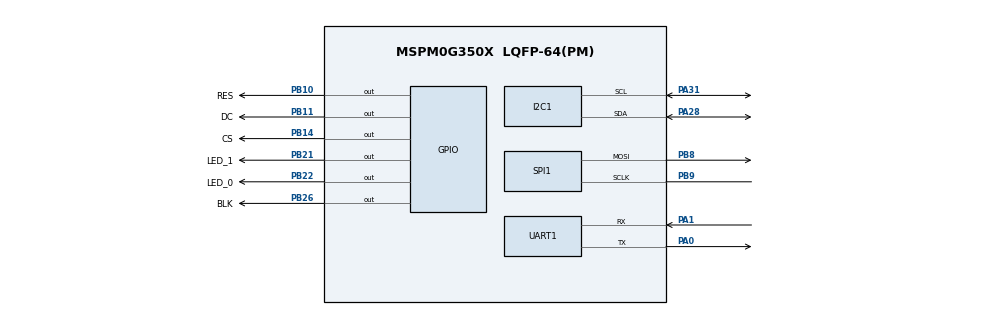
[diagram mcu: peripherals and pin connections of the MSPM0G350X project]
/**
 * @cliArgs --device "MSPM0G350X" --part "Default" --package "LQFP-64(PM)" --product "mspm0_sdk@2.10.00.04"
 * @versions {"tool":"1.26.2+4477"}
 */

/**
 * Import the modules used in this configuration.
 */
const GPIO   = scripting.addModule("/ti/driverlib/GPIO", {}, false);
const GPIO1  = GPIO.addInstance();
const GPIO2  = GPIO.addInstance();
const I2C    = scripting.addModule("/ti/driverlib/I2C", {}, false);
const I2C1   = I2C.addInstance();
const SPI    = scripting.addModule("/ti/driverlib/SPI", {}, false);
const SPI1   = SPI.addInstance();
const SYSCTL = scripting.addModule("/ti/driverlib/SYSCTL");
const UART   = scripting.addModule("/ti/driverlib/UART", {}, false);
const UART1  = UART.addInstance();

/**
 * Write custom configuration values to the imported modules.
 */
const divider9       = system.clockTree["UDIV"];
divider9.divideValue = 2;

const multiplier2         = system.clockTree["PLL_QDIV"];
multiplier2.multiplyValue = 4;

const mux4       = system.clockTree["EXHFMUX"];
mux4.inputSelect = "EXHFMUX_XTAL";

const mux8       = system.clockTree["HSCLKMUX"];
mux8.inputSelect = "HSCLKMUX_SYSPLL0";

const mux12       = system.clockTree["SYSPLLMUX"];
mux12.inputSelect = "zSYSPLLMUX_HFCLK";

const pinFunction4     = system.clockTree["HFXT"];
pinFunction4.inputFreq = 40;
pinFunction4.enable    = true;

GPIO1.$name                         = "LED";
GPIO1.associatedPins.create(2);
GPIO1.associatedPins[0].$name       = "LED_0";
GPIO1.associatedPins[0].pin.$assign = "PB22";
GPIO1.associatedPins[1].$name       = "LED_1";
GPIO1.associatedPins[1].pin.$assign = "PB21";

const Board = scripting.addModule("/ti/driverlib/Board", {}, false);

GPIO2.$name                         = "TFT_3";
GPIO2.associatedPins.create(4);
GPIO2.associatedPins[0].$name       = "RES";
GPIO2.associatedPins[0].pin.$assign = "PB10";
GPIO2.associatedPins[1].$name       = "DC";
GPIO2.associatedPins[1].pin.$assign = "PB11";
GPIO2.associatedPins[2].$name       = "CS";
GPIO2.associatedPins[2].pin.$assign = "PB14";
GPIO2.associatedPins[3].$name       = "BLK";
GPIO2.associatedPins[3].pin.$assign = "PB26";

I2C1.$name                             = "OLED";
I2C1.basicEnableController             = true;
I2C1.advDigitalGlitchFilter            = "CLOCKS_1";
I2C1.advControllerRXFIFOTRIG           = "BYTES_8";
I2C1.advControllerTXFIFOTRIG           = "BYTES_7";
I2C1.enableDMAEvent1                   = false;
I2C1.enableDMAEvent2                   = false;
I2C1.basicControllerStandardBusSpeed   = "Standard";
I2C1.peripheral.sdaPin.$assign         = "PA28";
I2C1.peripheral.sclPin.$assign         = "PA31";
I2C1.sdaPinConfig.$name                = "ti_driverlib_gpio_GPIOPinGeneric0";
I2C1.sdaPinConfig.hideOutputInversion  = scripting.forceWrite(false);
I2C1.sdaPinConfig.onlyInternalResistor = scripting.forceWrite(false);
I2C1.sdaPinConfig.passedPeripheralType = scripting.forceWrite("Digital");
I2C1.sdaPinConfig.enableConfig         = true;
I2C1.sdaPinConfig.internalResistor     = "PULL_UP";
I2C1.sclPinConfig.$name                = "ti_driverlib_gpio_GPIOPinGeneric1";
I2C1.sclPinConfig.hideOutputInversion  = scripting.forceWrite(false);
I2C1.sclPinConfig.onlyInternalResistor = scripting.forceWrite(false);
I2C1.sclPinConfig.passedPeripheralType = scripting.forceWrite("Digital");
I2C1.sclPinConfig.enableConfig         = true;
I2C1.sclPinConfig.internalResistor     = "PULL_UP";

SPI1.$name                              = "TFT";
SPI1.peripheral.$assign                 = "SPI1";
SPI1.peripheral.sclkPin.$assign         = "PB9";
SPI1.peripheral.mosiPin.$assign         = "PB8";
SPI1.sclkPinConfig.$name                = "ti_driverlib_gpio_GPIOPinGeneric2";
SPI1.sclkPinConfig.direction            = scripting.forceWrite("OUTPUT");
SPI1.sclkPinConfig.onlyInternalResistor = scripting.forceWrite(false);
SPI1.sclkPinConfig.passedPeripheralType = scripting.forceWrite("Digital");
SPI1.mosiPinConfig.$name                = "ti_driverlib_gpio_GPIOPinGeneric3";
SPI1.mosiPinConfig.direction            = scripting.forceWrite("OUTPUT");
SPI1.mosiPinConfig.hideOutputInversion  = scripting.forceWrite(false);
SPI1.mosiPinConfig.onlyInternalResistor = scripting.forceWrite(false);
SPI1.mosiPinConfig.passedPeripheralType = scripting.forceWrite("Digital");
SPI1.misoPinConfig.$name                = "ti_driverlib_gpio_GPIOPinGeneric4";
SPI1.misoPinConfig.onlyInternalResistor = scripting.forceWrite(false);
SPI1.misoPinConfig.passedPeripheralType = scripting.forceWrite("Digital");
SPI1.cs0PinConfig.$name                 = "ti_driverlib_gpio_GPIOPinGeneric5";
SPI1.cs0PinConfig.direction             = scripting.forceWrite("OUTPUT");
SPI1.cs0PinConfig.hideOutputInversion   = scripting.forceWrite(false);
SPI1.cs0PinConfig.onlyInternalResistor  = scripting.forceWrite(false);
SPI1.cs0PinConfig.passedPeripheralType  = scripting.forceWrite("Digital");

SYSCTL.forceDefaultClkConfig = true;
SYSCTL.clockTreeEn           = true;

UART1.$name                            = "Print";
UART1.targetBaudRate                   = 115200;
UART1.peripheral.$assign               = "UART0";
UART1.peripheral.rxPin.$assign         = "PA1";
UART1.peripheral.txPin.$assign         = "PA0";
UART1.txPinConfig.$name                = "ti_driverlib_gpio_GPIOPinGeneric6";
UART1.txPinConfig.direction            = scripting.forceWrite("OUTPUT");
UART1.txPinConfig.hideOutputInversion  = scripting.forceWrite(false);
UART1.txPinConfig.onlyInternalResistor = scripting.forceWrite(false);
UART1.txPinConfig.passedPeripheralType = scripting.forceWrite("Digital");
UART1.rxPinConfig.$name                = "ti_driverlib_gpio_GPIOPinGeneric7";
UART1.rxPinConfig.hideOutputInversion  = scripting.forceWrite(false);
UART1.rxPinConfig.onlyInternalResistor = scripting.forceWrite(false);
UART1.rxPinConfig.passedPeripheralType = scripting.forceWrite("Digital");

/**
 * Pinmux solution for unlocked pins/peripherals. This ensures that minor changes to the automatic solver in a future
 * version of the tool will not impact the pinmux you originally saw.  These lines can be completely deleted in order to
 * re-solve from scratch.
 */
pinFunction4.peripheral.$suggestSolution           = "SYSCTL";
pinFunction4.peripheral.hfxInPin.$suggestSolution  = "PA5";
pinFunction4.peripheral.hfxOutPin.$suggestSolution = "PA6";
Board.peripheral.$suggestSolution                  = "DEBUGSS";
Board.peripheral.swclkPin.$suggestSolution         = "PA20";
Board.peripheral.swdioPin.$suggestSolution         = "PA19";
I2C1.peripheral.$suggestSolution                   = "I2C0";
SPI1.peripheral.misoPin.$suggestSolution           = "PA16";
SPI1.peripheral.cs0Pin.$suggestSolution            = "PA2";
